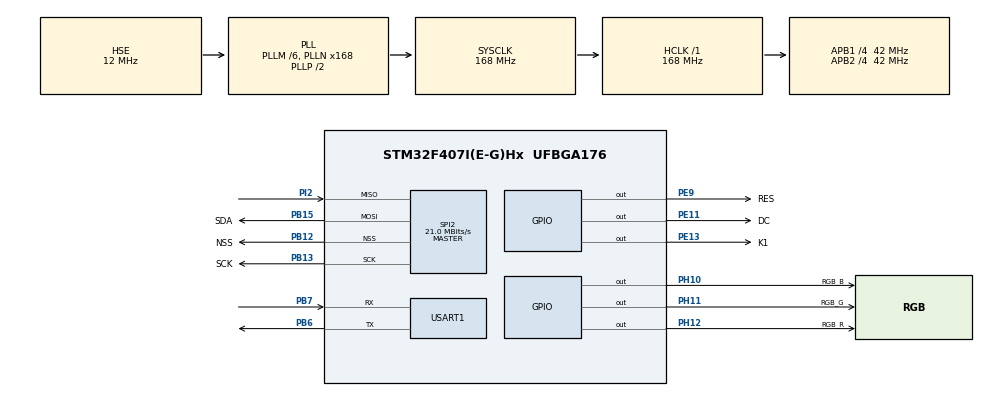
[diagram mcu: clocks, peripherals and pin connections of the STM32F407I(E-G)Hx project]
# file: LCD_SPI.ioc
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Mcu.Family=STM32F4
Mcu.Name=STM32F407I(E-G)Hx
Mcu.Package=UFBGA176
NVIC.PriorityGroup=NVIC_PRIORITYGROUP_4
NVIC.USART1_IRQn=true\:0\:0\:false\:false\:true\:true\:true\:true
PA13.Mode=Serial_Wire
PA13.Signal=SYS_JTMS-SWDIO
PA14.Mode=Serial_Wire
PA14.Signal=SYS_JTCK-SWCLK
PB12.GPIO_Label=NSS
PB12.Mode=NSS_Signal_Hard_Output
PB12.Signal=SPI2_NSS
PB13.GPIO_Label=SCK
PB13.Mode=Full_Duplex_Master
PB13.Signal=SPI2_SCK
PB15.GPIO_Label=SDA
PB15.Mode=Full_Duplex_Master
PB15.Signal=SPI2_MOSI
PB6.Mode=Asynchronous
PB6.Signal=USART1_TX
PB7.Mode=Asynchronous
PB7.Signal=USART1_RX
PE11.GPIO_Label=DC
PE11.Signal=GPIO_Output
PE13.GPIO_Label=K1
PE13.Signal=GPIO_Output
PE9.GPIO_Label=RES
PE9.Signal=GPIO_Output
PH0-OSC_IN.Mode=HSE-External-Oscillator
PH0-OSC_IN.Signal=RCC_OSC_IN
PH1-OSC_OUT.Mode=HSE-External-Oscillator
PH1-OSC_OUT.Signal=RCC_OSC_OUT
PH10.GPIO_Label=RGB_B
PH10.Signal=GPIO_Output
PH11.GPIO_Label=RGB_G
PH11.Signal=GPIO_Output
PH12.GPIO_Label=RGB_R
PH12.Signal=GPIO_Output
PI2.Mode=Full_Duplex_Master
PI2.Signal=SPI2_MISO
ProjectManager.HeapSize=0x200
ProjectManager.StackSize=0x400
ProjectManager.TargetToolchain=MDK-ARM V5.32
RCC.48MHZClocksFreq_Value=84000000
RCC.AHBFreq_Value=168000000
RCC.APB1CLKDivider=RCC_HCLK_DIV4
RCC.APB1Freq_Value=42000000
RCC.APB1TimFreq_Value=84000000
RCC.APB2CLKDivider=RCC_HCLK_DIV4
RCC.APB2Freq_Value=42000000
RCC.APB2TimFreq_Value=84000000
RCC.CortexFreq_Value=168000000
RCC.HCLKFreq_Value=168000000
RCC.HSE_VALUE=12000000
RCC.HSI_VALUE=16000000
RCC.LSE_VALUE=32768
RCC.PLLM=6
RCC.PLLN=168
RCC.PLLSourceVirtual=RCC_PLLSOURCE_HSE
RCC.SYSCLKFreq_VALUE=168000000
RCC.SYSCLKSource=RCC_SYSCLKSOURCE_PLLCLK
RCC.VCOOutputFreq_Value=336000000
SPI2.BaudRatePrescaler=SPI_BAUDRATEPRESCALER_2
SPI2.CalculateBaudRate=21.0 MBits/s
SPI2.Direction=SPI_DIRECTION_2LINES
SPI2.Mode=SPI_MODE_MASTER
SPI2.VirtualNSS=VM_NSSHARD
SPI2.VirtualType=VM_MASTER
USART1.VirtualMode=VM_ASYNC
board=custom

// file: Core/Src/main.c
/* USER CODE BEGIN Header */
/**
  ******************************************************************************
  * @file           : main.c
  * @brief          : Main program body
  ******************************************************************************
  * @attention
  *
  * Copyright (c) 2024 STMicroelectronics.
  * All rights reserved.
  *
  * This software is licensed under terms that can be found in the LICENSE file
  * in the root directory of this software component.
  * If no LICENSE file comes with this software, it is provided AS-IS.
  *
  ******************************************************************************
  */
/* USER CODE END Header */
#include "main.h"

/* USER CODE BEGIN Includes */
#include "LCD.h"
/* USER CODE END Includes */

SPI_HandleTypeDef hspi2;

UART_HandleTypeDef huart1;

void SystemClock_Config(void);
static void MX_GPIO_Init(void);
static void MX_SPI2_Init(void);
static void MX_USART1_UART_Init(void);

int main(void)
{

  /* MCU Configuration--------------------------------------------------------*/

  /* Reset of all peripherals, Initializes the Flash interface and the Systick. */
  HAL_Init();

  /* Configure the system clock */
  SystemClock_Config();

  /* Initialize all configured peripherals */
  MX_GPIO_Init();
  MX_SPI2_Init();
  MX_USART1_UART_Init();
  /* USER CODE BEGIN 2 */
  LCD_Init(&hspi2);
  LCD_Img = gImage_sputnik;
  LCD_ShowImg(&hspi2);
	HAL_Delay(500);
  /* USER CODE END 2 */

  /* Infinite loop */
  while (1)
  {
    //LED交替闪烁证明程序运行
    HAL_GPIO_TogglePin(GPIOH, RGB_R_Pin);
    HAL_Delay(50);
    HAL_GPIO_TogglePin(GPIOH, RGB_R_Pin);
    HAL_Delay(50);
    HAL_GPIO_TogglePin(GPIOH, RGB_G_Pin);
    HAL_Delay(50);
    HAL_GPIO_TogglePin(GPIOH, RGB_G_Pin);
    HAL_Delay(50);
    HAL_GPIO_TogglePin(GPIOH, RGB_B_Pin);
    HAL_Delay(50);
    HAL_GPIO_TogglePin(GPIOH, RGB_B_Pin);
    HAL_Delay(50);
    // LCD_SetRegion(&hspi2,0, 0, 239, 239);
    // uint8_t cmd_white = 0xFF;
    // for (int i = 0; i < 57600; i++)
    // {
    //     HAL_SPI_Transmit(&hspi2, &cmd_white, 1, 100);
    //     HAL_SPI_Transmit(&hspi2, &cmd_white, 1, 100);
    // }

  }
}

void SystemClock_Config(void)
{
  RCC_OscInitTypeDef RCC_OscInitStruct = {0};
  RCC_ClkInitTypeDef RCC_ClkInitStruct = {0};

  /** Configure the main internal regulator output voltage
  */
  __HAL_RCC_PWR_CLK_ENABLE();
  __HAL_PWR_VOLTAGESCALING_CONFIG(PWR_REGULATOR_VOLTAGE_SCALE1);

  /** Initializes the RCC Oscillators according to the specified parameters
  * in the RCC_OscInitTypeDef structure.
  */
  RCC_OscInitStruct.OscillatorType = RCC_OSCILLATORTYPE_HSE;
  RCC_OscInitStruct.HSEState = RCC_HSE_ON;
  RCC_OscInitStruct.PLL.PLLState = RCC_PLL_ON;
  RCC_OscInitStruct.PLL.PLLSource = RCC_PLLSOURCE_HSE;
  RCC_OscInitStruct.PLL.PLLM = 6;
  RCC_OscInitStruct.PLL.PLLN = 168;
  RCC_OscInitStruct.PLL.PLLP = RCC_PLLP_DIV2;
  RCC_OscInitStruct.PLL.PLLQ = 4;
  if (HAL_RCC_OscConfig(&RCC_OscInitStruct) != HAL_OK)
  {
    Error_Handler();
  }

  /** Initializes the CPU, AHB and APB buses clocks
  */
  RCC_ClkInitStruct.ClockType = RCC_CLOCKTYPE_HCLK|RCC_CLOCKTYPE_SYSCLK
                              |RCC_CLOCKTYPE_PCLK1|RCC_CLOCKTYPE_PCLK2;
  RCC_ClkInitStruct.SYSCLKSource = RCC_SYSCLKSOURCE_PLLCLK;
  RCC_ClkInitStruct.AHBCLKDivider = RCC_SYSCLK_DIV1;
  RCC_ClkInitStruct.APB1CLKDivider = RCC_HCLK_DIV4;
  RCC_ClkInitStruct.APB2CLKDivider = RCC_HCLK_DIV4;

  if (HAL_RCC_ClockConfig(&RCC_ClkInitStruct, FLASH_LATENCY_5) != HAL_OK)
  {
    Error_Handler();
  }
}

static void MX_SPI2_Init(void)
{

  /* SPI2 parameter configuration*/
  hspi2.Instance = SPI2;
  hspi2.Init.Mode = SPI_MODE_MASTER;
  hspi2.Init.Direction = SPI_DIRECTION_2LINES;
  hspi2.Init.DataSize = SPI_DATASIZE_8BIT;
  hspi2.Init.CLKPolarity = SPI_POLARITY_LOW;
  hspi2.Init.CLKPhase = SPI_PHASE_1EDGE;
  hspi2.Init.NSS = SPI_NSS_HARD_OUTPUT;
  hspi2.Init.BaudRatePrescaler = SPI_BAUDRATEPRESCALER_2;
  hspi2.Init.FirstBit = SPI_FIRSTBIT_MSB;
  hspi2.Init.TIMode = SPI_TIMODE_DISABLE;
  hspi2.Init.CRCCalculation = SPI_CRCCALCULATION_DISABLE;
  hspi2.Init.CRCPolynomial = 7;
  if (HAL_SPI_Init(&hspi2) != HAL_OK)
  {
    Error_Handler();
  }

}

static void MX_USART1_UART_Init(void)
{

  huart1.Instance = USART1;
  huart1.Init.BaudRate = 115200;
  huart1.Init.WordLength = UART_WORDLENGTH_8B;
  huart1.Init.StopBits = UART_STOPBITS_1;
  huart1.Init.Parity = UART_PARITY_NONE;
  huart1.Init.Mode = UART_MODE_TX_RX;
  huart1.Init.HwFlowCtl = UART_HWCONTROL_NONE;
  huart1.Init.OverSampling = UART_OVERSAMPLING_16;
  if (HAL_UART_Init(&huart1) != HAL_OK)
  {
    Error_Handler();
  }

}

static void MX_GPIO_Init(void)
{
  GPIO_InitTypeDef GPIO_InitStruct = {0};

  /* GPIO Ports Clock Enable */
  __HAL_RCC_GPIOA_CLK_ENABLE();
  __HAL_RCC_GPIOB_CLK_ENABLE();
  __HAL_RCC_GPIOI_CLK_ENABLE();
  __HAL_RCC_GPIOH_CLK_ENABLE();
  __HAL_RCC_GPIOE_CLK_ENABLE();

  /*Configure GPIO pin Output Level */
  HAL_GPIO_WritePin(GPIOH, RGB_R_Pin|RGB_G_Pin|RGB_B_Pin, GPIO_PIN_RESET);

  /*Configure GPIO pin Output Level */
  HAL_GPIO_WritePin(GPIOE, K1_Pin|RES_Pin|DC_Pin, GPIO_PIN_RESET);

  /*Configure GPIO pins : RGB_R_Pin RGB_G_Pin RGB_B_Pin */
  GPIO_InitStruct.Pin = RGB_R_Pin|RGB_G_Pin|RGB_B_Pin;
  GPIO_InitStruct.Mode = GPIO_MODE_OUTPUT_PP;
  GPIO_InitStruct.Pull = GPIO_NOPULL;
  GPIO_InitStruct.Speed = GPIO_SPEED_FREQ_LOW;
  HAL_GPIO_Init(GPIOH, &GPIO_InitStruct);

  /*Configure GPIO pins : K1_Pin RES_Pin DC_Pin */
  GPIO_InitStruct.Pin = K1_Pin|RES_Pin|DC_Pin;
  GPIO_InitStruct.Mode = GPIO_MODE_OUTPUT_PP;
  GPIO_InitStruct.Pull = GPIO_NOPULL;
  GPIO_InitStruct.Speed = GPIO_SPEED_FREQ_LOW;
  HAL_GPIO_Init(GPIOE, &GPIO_InitStruct);

}

void Error_Handler(void)
{
  __disable_irq();
  while (1)
  {
  }
}
